AUTOSAR XML (schema 314)
package /ComponentType
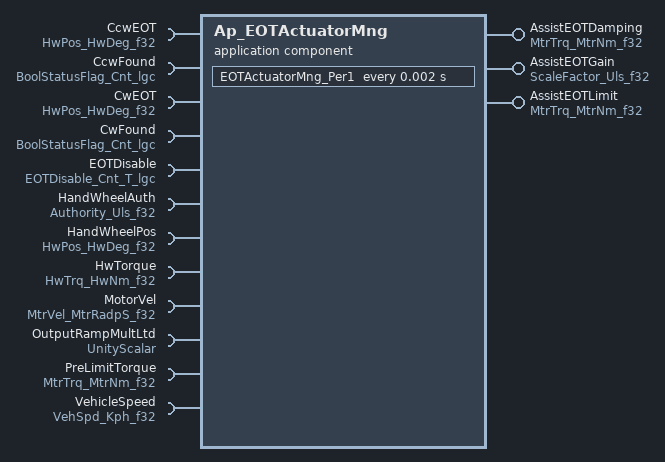
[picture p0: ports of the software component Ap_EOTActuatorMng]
  application software component type Ap_EOTActuatorMng
    provide port AssistEOTDamping: unqueued-sender-com-spec{data-element=MtrNm_f32, can-invalidate=false, init-value=D_ZERO_ULS_F32}, provided-interface=MtrTrq_MtrNm_f32
    provide port AssistEOTGain: unqueued-sender-com-spec{data-element=Uls_f32, can-invalidate=false, init-value=D_ONE_ULS_F32}, provided-interface=ScaleFactor_Uls_f32
    provide port AssistEOTLimit: unqueued-sender-com-spec{data-element=MtrNm_f32, can-invalidate=false, init-value=D_MTRTRQCMDHILMT_MTRNM_F32}, provided-interface=MtrTrq_MtrNm_f32
    12 x require port:
      CcwEOT: unqueued-receiver-com-spec{data-element=HwDeg_f32, init-value=D_ZERO_ULS_F32}, required-interface=HwPos_HwDeg_f32
      CcwFound: unqueued-receiver-com-spec{data-element=Cnt_lgc, init-value=D_FALSE_CNT_LGC}, required-interface=BoolStatusFlag_Cnt_lgc
      CwEOT: unqueued-receiver-com-spec{data-element=HwDeg_f32, init-value=D_ZERO_ULS_F32}, required-interface=HwPos_HwDeg_f32
      CwFound: unqueued-receiver-com-spec{data-element=Cnt_lgc, init-value=D_FALSE_CNT_LGC}, required-interface=BoolStatusFlag_Cnt_lgc
      EOTDisable: unqueued-receiver-com-spec{data-element=Cnt_lgc, init-value=D_FALSE_CNT_LGC}, required-interface=EOTDisable_Cnt_T_lgc
      HandWheelAuth: unqueued-receiver-com-spec{data-element=Uls_f32, init-value=D_ZERO_ULS_F32}, required-interface=Authority_Uls_f32
      HandWheelPos: unqueued-receiver-com-spec{data-element=HwDeg_f32, init-value=D_ZERO_ULS_F32}, required-interface=HwPos_HwDeg_f32
      HwTorque: unqueued-receiver-com-spec{data-element=HwNm_f32, init-value=D_ZERO_ULS_F32}, required-interface=HwTrq_HwNm_f32
      MotorVel: unqueued-receiver-com-spec{data-element=MtrRadpS_f32, init-value=D_ZERO_ULS_F32}, required-interface=MtrVel_MtrRadpS_f32
      OutputRampMultLtd: unqueued-receiver-com-spec{data-element=Uls_f32, init-value=D_ZERO_ULS_F32}, required-interface=UnityScalar
      PreLimitTorque: unqueued-receiver-com-spec{data-element=MtrNm_f32, init-value=D_ZERO_ULS_F32}, required-interface=MtrTrq_MtrNm_f32
      VehicleSpeed: unqueued-receiver-com-spec{data-element=Kph_f32, init-value=D_ZERO_ULS_F32}, required-interface=VehSpd_Kph_f32
  internal behavior Ap_EOTActuatorMng_InternalBehavior: component=Ap_EOTActuatorMng
    timing event TMT_EOTActuatorMng_Per1: start-on-event=EOTActuatorMng_Per1, period=0.002
    port-api-options:
      enable-take-address=false, indirect-api=false, port=AssistEOTDamping
      enable-take-address=false, indirect-api=false, port=AssistEOTGain
      enable-take-address=false, indirect-api=false, port=AssistEOTLimit
      enable-take-address=false, indirect-api=false, port=CcwEOT
      enable-take-address=false, indirect-api=false, port=CcwFound
      enable-take-address=false, indirect-api=false, port=CwEOT
      enable-take-address=false, indirect-api=false, port=CwFound
      enable-take-address=false, indirect-api=false, port=EOTDisable
      enable-take-address=false, indirect-api=false, port=HandWheelAuth
      enable-take-address=false, indirect-api=false, port=HandWheelPos
      enable-take-address=false, indirect-api=false, port=HwTorque
      enable-take-address=false, indirect-api=false, port=MotorVel
      enable-take-address=false, indirect-api=false, port=OutputRampMultLtd
      enable-take-address=false, indirect-api=false, port=PreLimitTorque
      enable-take-address=false, indirect-api=false, port=VehicleSpeed
    runnable EOTActuatorMng_Per1
      12 x data read access:
        READ_CcwEOT_HwDeg_f32: data-element=CcwEOT.HwDeg_f32
        READ_CcwFound_Cnt_lgc: data-element=CcwFound.Cnt_lgc
        READ_CwEOT_HwDeg_f32: data-element=CwEOT.HwDeg_f32
        READ_CwFound_Cnt_lgc: data-element=CwFound.Cnt_lgc
        READ_EOTDisable_Cnt_lgc: data-element=EOTDisable.Cnt_lgc
        READ_HandWheelAuth_Uls_f32: data-element=HandWheelAuth.Uls_f32
        READ_HandWheelPos_HwDeg_f32: data-element=HandWheelPos.HwDeg_f32
        READ_HwTorque_HwNm_f32: data-element=HwTorque.HwNm_f32
        READ_MotorVel_MtrRadpS_f32: data-element=MotorVel.MtrRadpS_f32
        READ_OutputRampMultLtd_Uls_f32: data-element=OutputRampMultLtd.Uls_f32
        READ_PreLimitTorque_MtrNm_f32: data-element=PreLimitTorque.MtrNm_f32
        READ_VehicleSpeed_Kph_f32: data-element=VehicleSpeed.Kph_f32
      data write access WRITE_AssistEOTDamping_MtrNm_f32: data-element=AssistEOTDamping.MtrNm_f32
      data write access WRITE_AssistEOTGain_Uls_f32: data-element=AssistEOTGain.Uls_f32
      data write access WRITE_AssistEOTLimit_MtrNm_f32: data-element=AssistEOTLimit.MtrNm_f32
  swc implementation Ap_EOTActuatorMng_Implementation: behavior=Ap_EOTActuatorMng_InternalBehavior
    code-descriptors:
      code Code: type=SRC
